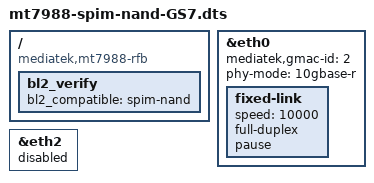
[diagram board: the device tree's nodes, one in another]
// SPDX-License-Identifier: GPL-2.0
/*
 * Copyright (c) 2022 MediaTek Inc.
 * Author: Sam Shih <sam.shih@mediatek.com>
 */

/dts-v1/;
#include "mt7988-rfb.dts"
#include <dt-bindings/gpio/gpio.h>

/ {
	compatible = "mediatek,mt7988-rfb", "mediatek,mt7988-spim-nand-rfb";

	bl2_verify {
		bl2_compatible = "spim-nand";
	};

};

&eth0 {
	status = "okay";
	mediatek,gmac-id = <2>;
	phy-mode = "10gbase-r";
	/delete-property/ mediatek,switch;

	fixed-link {
		speed = <10000>;
		full-duplex;
		pause;
	};
};

&eth2 {
	status = "disabled";
};
